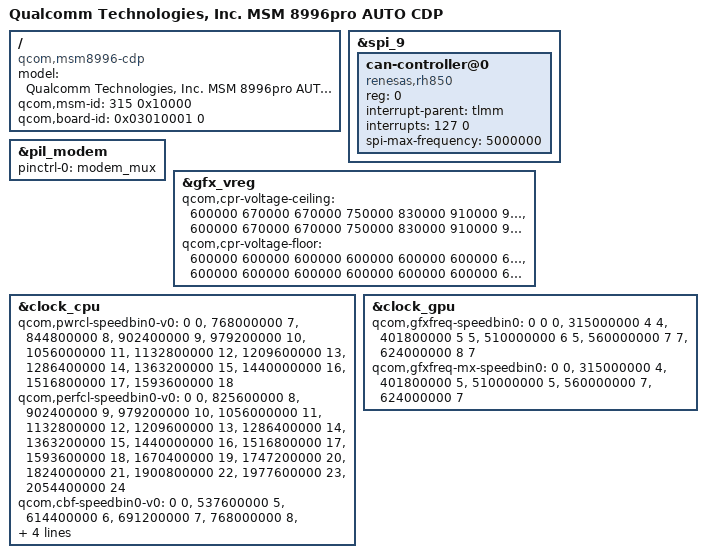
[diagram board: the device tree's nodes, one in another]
/* Copyright (c) 2015-2016, The Linux Foundation. All rights reserved.
 *
 * This program is free software; you can redistribute it and/or modify
 * it under the terms of the GNU General Public License version 2 and
 * only version 2 as published by the Free Software Foundation.
 *
 * This program is distributed in the hope that it will be useful,
 * but WITHOUT ANY WARRANTY; without even the implied warranty of
 * MERCHANTABILITY or FITNESS FOR A PARTICULAR PURPOSE.  See the
 * GNU General Public License for more details.
 */

/dts-v1/;

#include "msm8996pro.dtsi"
#include "msm8996-pm8994.dtsi"
#include "msm8996-auto-cdp.dtsi"

/ {
	model = "Qualcomm Technologies, Inc. MSM 8996pro AUTO CDP";
	compatible = "qcom,msm8996-cdp", "qcom,msm8996", "qcom,cdp";
	qcom,msm-id = <315 0x10000>;
	qcom,board-id = <0x03010001 0>;
};

&spi_9 {
	status = "ok";
	can-controller@0 {
		compatible = "renesas,rh850";
		reg = <0>;
		interrupt-parent = <&tlmm>;
		interrupts = <127 0>;
		spi-max-frequency = <5000000>;
	};
};

&pil_modem {
	pinctrl-names = "default";
	pinctrl-0 = <&modem_mux>;
};

&gfx_vreg {
	qcom,cpr-voltage-ceiling =
		/* Speed bin 0 */
		<600000  670000  670000  750000  830000  910000  960000 1020000
		1070000>,

		/* Speed bin 1 */
		<600000  670000  670000  750000  830000  910000  960000 1020000
		1070000>;

	qcom,cpr-voltage-floor =
		/* Speed bin 0 */
		<600000  600000  600000  600000  600000  600000  600000  600000
		 600000>,

		/* Speed bin 1 */
		<600000  600000  600000  600000  600000  600000  600000  600000
		 600000>;
};

&clock_cpu {
	qcom,pwrcl-speedbin0-v0 =
		<          0  0 >,
		<  768000000  7 >,
		<  844800000  8 >,
		<  902400000  9 >,
		<  979200000 10 >,
		< 1056000000 11 >,
		< 1132800000 12 >,
		< 1209600000 13 >,
		< 1286400000 14 >,
		< 1363200000 15 >,
		< 1440000000 16 >,
		< 1516800000 17 >,
		< 1593600000 18 >;

	qcom,perfcl-speedbin0-v0 =
		<          0  0 >,
		<  825600000  8 >,
		<  902400000  9 >,
		<  979200000 10 >,
		< 1056000000 11 >,
		< 1132800000 12 >,
		< 1209600000 13 >,
		< 1286400000 14 >,
		< 1363200000 15 >,
		< 1440000000 16 >,
		< 1516800000 17 >,
		< 1593600000 18 >,
		< 1670400000 19 >,
		< 1747200000 20 >,
		< 1824000000 21 >,
		< 1900800000 22 >,
		< 1977600000 23 >,
		< 2054400000 24 >;

	qcom,cbf-speedbin0-v0 =
		<	   0  0 >,
		<  537600000  5 >,
		<  614400000  6 >,
		<  691200000  7 >,
		<  768000000  8 >,
		<  844800000  9 >,
		<  902400000 10 >,
		<  979200000 11 >,
		< 1056000000 12 >,
		< 1132800000 13 >,
		< 1190400000 14 >,
		< 1286400000 15 >,
		< 1363200000 16 >,
		< 1440000000 17 >,
		< 1516800000 18 >,
		< 1593600000 19 >;
};

&clock_gpu {
	qcom,gfxfreq-speedbin0 =
		<          0  0  0 >,
		<  315000000  4  4 >,
		<  401800000  5  5 >,
		<  510000000  6  5 >,
		<  560000000  7  7 >,
		<  624000000  8  7 >;

	qcom,gfxfreq-mx-speedbin0 =
		<          0  0 >,
		<  315000000  4 >,
		<  401800000  5 >,
		<  510000000  5 >,
		<  560000000  7 >,
		<  624000000  7 >;
};
